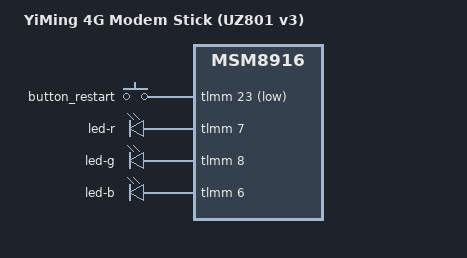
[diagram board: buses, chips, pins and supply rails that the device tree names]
// SPDX-License-Identifier: GPL-2.0-only

/dts-v1/;

#include "msm8916-ufi.dtsi"

/ {
	model = "YiMing 4G Modem Stick (UZ801 v3)";
	compatible = "yiming,uz801-v3", "qcom,msm8916";
};

&button_restart {
	gpios = <&tlmm 23 GPIO_ACTIVE_LOW>;
};

&leds {
	led-r {
		gpios = <&tlmm 7 GPIO_ACTIVE_HIGH>;
	};

	led-g {
		gpios = <&tlmm 8 GPIO_ACTIVE_HIGH>;
	};

	led-b {
		gpios = <&tlmm 6 GPIO_ACTIVE_HIGH>;
	};
};

&button_default {
	pins = "gpio23";
	bias-pull-up;
};

&gpio_leds_default {
	pins = "gpio6", "gpio7", "gpio8";
};
